# N570F064_v4_2 register map
File version: 1.0
Registers are 32-bit, read-write, reset 0x0 unless marked. A register's access mark holds for its fields unless they carry their own. Offsets are from the block's base; [hi:lo] are bit positions.

## DPWM — DPWM Register Map
Base 0x40070000
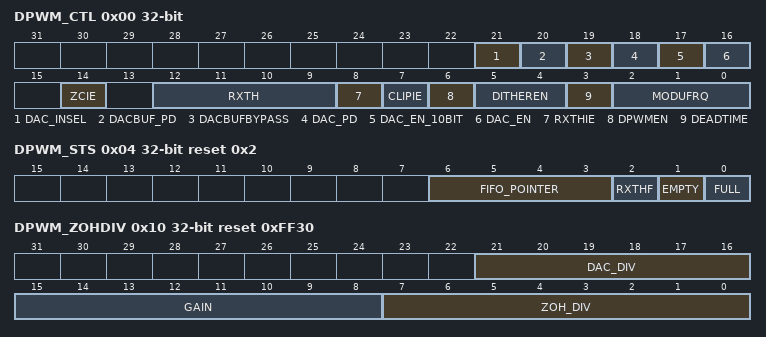
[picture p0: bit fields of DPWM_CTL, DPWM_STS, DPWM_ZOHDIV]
0x00 DPWM_CTL — DPWM and DAC Control Register
  [21] DAC_INSEL — DAC input data selection. 0 --- DATA from CIC and GAIN output. 1 --- DATA from FIFO output
  [20] DACBUF_PD — DAC BUFFER POWER DOWN. 0 --- power on DAC BUFFER. 1 --- power off DAC BUFFER
  [19] DACBUFBYPASS — DAC BUFFER BYPASS. 0 --- disable BYPASS DAC BUFFER. 1 --- enable BYPASS DAC BUFFER
  [18] DAC_PD — DAC POWER DOWN. 0 --- power on DAC13B. 1 --- power down DAC13B
  [17] DAC_EN_10BIT — DAC ENABLE 10Bit. 0 --- 13 Bit mode. 1 --- 10 bit mode, don't use lower 3BITs
  [16] DAC_EN — DAC ENABLE. 0 --- DAC function disable. 1 --- DAC function enable
  [14] ZCIE — Zero cross enable. 0: output data doesn't cross zero point. 1: output data cross zero point
  [12:9] RXTH — DPWM FIFO threshold. If the valid data count of the DPWM FIFO buffer is less than or equal to RXTH setting, the RXTHF bit will set to 1, else the RXTHF bit will be cleared to 0.
  [8] RXTHIE — DPWM FIFO threshold interrupt. 1: DPWM FIFO threshold interrupt Enabled. 0: DPWM FIFO threshold interrupt Disabled.
  [7] CLIPIE — Read data in DATA[31:0] clipped within 0x0000-7fff ~ 0xffff-8000. Read operation of this register will get clipped data in DATA[31:0] register but clipped with the range : 0x00 ~ 7fff ~ 0x ffff ~8000. The content of DATA[31:0] will not be change.
  [6] DPWMEN — DPWM Enable. 1: Enable DPWM, SPK pins are enabled and driven, data is taken from FIFO. 0: Disable DPWM, SPK pins are tri-state, CIC filter is reset, FIFO pointers are reset (FIFO data is not reset). Note : This field will be effective only when DAC_EN field in this register is set as "0".
  [5:4] DITHEREN — DPWM Signal Dither Control. To prevent structured noise on PWM output due to DC offsets in the input signal it is possible to add random dither to the PWM signal. These bits control the dither: 0: No dither. 1: ±1 bit dither. 3: ±2 bit dither
  [3] DEADTIME — DPWM Driver Deadtime Control. Enabling this bit will insert an additional clock cycle deadtime into the switching of PMOS and NMOS driver transistors.
  [2:0] MODUFRQ — DPWM Modulation Frequency.
0x04 DPWM_STS ro reset 0x2 — DPWM and DAC FIFO Status Register
  [6:3] FIFO_POINTER — DPWM FIFO Pointer (Read Only). The FULL bit and FIFO_POINTER[3:0] indicates the field that the valid data count within the DPWM FIFO buffer. The Maximum value shown in FIFO_POINTER is 15. When the using level of DPWM FIFO Buffer equal to 16, The FULL bit is set to 1.
  [2] RXTHF — DPWM FIFO threshold Interrupt Status (Read Only)
    0=The valid data count within the DPWM FIFO buffer is larger than the setting value of RXTH; 1=The valid data count within the transmit FIFO buffer is less than or equal to the setting value of RXTH
  [1] EMPTY — FIFO Empty
    0=FIFO is not empty; 1=FIFO is empty
  [0] FULL — FIFO Full
    0=FIFO is not full; 1=FIFO is full
0x08 DPWM_DMACTL — DPWM and DAC PDMA Control Register
  [0] DMAEN — Enable DPWM and DAC DMA Interface.
    0=Disable PDMA. No requests will be made to PDMA controller; 1=Enable PDMA. Block will request data from PDMA controller whenever FIFO is not empty
0x0C DPWM_DATA wo — DPWM and DAC FIFO Input Register
  [15:0] INDATA — DPWM and DAC FIFO Audio Data Input. A write to this register pushes data onto the DPWM and DAC FIFO and increments the write pointer. This is the address that PDMA writes audio data to.
0x10 DPWM_ZOHDIV reset 0xFF30 — DPWM and DAC Zero Order Hold Division Register
  [21:16] DAC_DIV — DAC clock divider. DAC data sample rate is set by this divider
  [15:8] GAIN — (GAIN[7:0]+1)/256, GAIN≠0
  [7:0] ZOH_DIV — DPWM Zero Order Hold, down-sampling divisor. The input sample rate of the DPWM is set by HCLK frequency and the divisor set in this register by the following formula: Valid range is 1,..,255. Default is 48, which gives a sample rate of 16kHz for a 49.152MHz (default) HCLK.
